VERSION ""

NS_ :

BS_:

BU_: SCU ADCU

BO_ 3221225472 VECTOR__INDEPENDENT_SIG_MSG: 0 Vector__XXX
 SG_ ADCU_SteerAngSpdLimt : 0|16@0+ (0.125,0) [0|1080] "deg/s" Vector__XXX
 SG_ ADCU_SteerWhlTorqReq : 0|11@0+ (0.01,-10.24) [-10.24|10.23] "Nm" Vector__XXX
 SG_ New_Signal_168 : 0|8@1+ (1,0) [0|0] "" Vector__XXX
 SG_ ADCU_3_Checksum : 0|8@0+ (1,0) [0|255] "-" Vector__XXX
 SG_ ADCU_3_MsgCounter : 0|4@0+ (1,0) [0|15] "-" Vector__XXX
 SG_ ADCU_2_Checksum : 0|8@0+ (1,0) [0|255] "" Vector__XXX
 SG_ ADCU_2_MsgCounter : 0|4@0+ (1,0) [0|15] "" Vector__XXX
 SG_ ADCU_1_Checksum : 0|8@0+ (1,0) [0|255] "" Vector__XXX
 SG_ ADCU_1_MsgCounter : 0|4@0+ (1,0) [0|15] "" Vector__XXX
 SG_ SCU_18_Checksum : 0|8@0+ (1,0) [0|255] "-" Vector__XXX
 SG_ VCU_GasPedalVirtualPstVD : 0|1@0+ (1,0) [0|1] "" Vector__XXX
 SG_ VCU_BrkPedalStVD : 0|1@0+ (1,0) [0|1] "" Vector__XXX
 SG_ SCU_18_MsgCounter : 0|4@0+ (1,0) [0|15] "-" Vector__XXX
 SG_ VCU_GasPedalVirtualPst : 0|8@0+ (0.392,0) [0|99.96] "%" Vector__XXX
 SG_ SCU_17_Checksum : 0|8@0+ (1,0) [0|255] "-" Vector__XXX
 SG_ SCU_17_MsgCounter : 0|4@0+ (1,0) [0|15] "-" Vector__XXX
 SG_ VCU_ACCButtInfo : 0|8@0+ (1,0) [0|255] "" Vector__XXX
 SG_ VCU_GasPedalActPstVD : 0|1@0+ (1,0) [0|1] "" Vector__XXX
 SG_ SCU_16_Checksum : 0|8@0+ (1,0) [0|205] "-" Vector__XXX
 SG_ SCU_16_MsgCounter : 0|4@0+ (1,0) [0|15] "-" Vector__XXX
 SG_ VCU_LateralAssistBtnInfoVD : 0|1@0+ (1,0) [0|1] "" Vector__XXX
 SG_ VCU_LateralAssistBtnInfo : 0|1@0+ (1,0) [0|1] "" Vector__XXX
 SG_ VCU_ACCMaxRecpDecelVD : 0|1@0+ (1,0) [0|1] "" Vector__XXX
 SG_ VCU_ACCMaxRecpDecel : 0|8@0+ (0.05,-5) [-5|7.75] "m/s2" Vector__XXX
 SG_ VCU_ActRecpTorq : 0|10@0+ (2,0) [0|2000] "Nm" Vector__XXX
 SG_ VCU_ActRecpTorqSt : 0|2@0+ (1,0) [0|3] "" Vector__XXX
 SG_ SCU_13_Checksum : 0|8@0+ (1,0) [0|255] "" Vector__XXX
 SG_ SCU_13_MsgCounter : 0|4@0+ (1,0) [0|15] "" Vector__XXX
 SG_ SCU_EStopSwStVD : 0|1@0+ (1,0) [0|1] "" Vector__XXX
 SG_ SCU_EStopSwSt : 0|1@0+ (1,0) [0|1] "" Vector__XXX
 SG_ SCU_12_Checksum : 0|8@0+ (1,0) [0|255] "" Vector__XXX
 SG_ SCU_12_MsgCounter : 0|4@0+ (1,0) [0|15] "" Vector__XXX
 SG_ SCU_11_Checksum : 0|8@0+ (1,0) [0|255] "" Vector__XXX
 SG_ SCU_11_MsgCounter : 0|4@0+ (1,0) [0|15] "" Vector__XXX
 SG_ BCM_RightTurnLampFaultSt : 0|1@0+ (1,0) [0|1] "" Vector__XXX
 SG_ BCM_LeftTurnLampFaultSt : 0|1@0+ (1,0) [0|1] "" Vector__XXX
 SG_ BCM_RRDoorAjarSt : 0|1@0+ (1,0) [0|1] "" Vector__XXX
 SG_ BCM_RLDoorAjarSt : 0|1@0+ (1,0) [0|1] "" Vector__XXX
 SG_ BCM_PsngrDoorAjarSt : 0|1@0+ (1,0) [0|1] "" Vector__XXX
 SG_ BCM_DriverDoorAjarSt : 0|1@0+ (1,0) [0|1] "" Vector__XXX
 SG_ BCM_RearFogLampSt : 0|1@0+ (1,0) [0|1] "" Vector__XXX
 SG_ BCM_FrontFogLampSt : 0|1@0+ (1,0) [0|1] "" Vector__XXX
 SG_ BCM_FrontWiperSt : 0|2@0+ (1,0) [0|3] "" Vector__XXX
 SG_ SCU_10_Checksum : 0|8@0+ (1,0) [0|255] "" Vector__XXX
 SG_ EPS_ThermalSt : 0|2@0+ (1,0) [0|3] "" Vector__XXX
 SG_ SCU_10_MsgCounter : 0|4@0+ (1,0) [0|15] "" Vector__XXX
 SG_ EPS_WarnLamp : 0|1@0+ (1,0) [0|1] "" Vector__XXX
 SG_ EPS_StrngWhlTorqVD : 0|1@0+ (1,0) [0|1] "" Vector__XXX
 SG_ SCU_9_Checksum : 0|8@0+ (1,0) [0|255] "" Vector__XXX
 SG_ EPB_FailSt : 0|1@0+ (1,0) [0|1] "" Vector__XXX
 SG_ SCU_9_MsgCounter : 0|4@0+ (1,0) [0|15] "" Vector__XXX
 SG_ EPB_SwitchStVD : 0|1@0+ (1,0) [0|1] "" Vector__XXX
 SG_ EPB_SwitchSt : 0|2@0+ (1,0) [0|3] "" Vector__XXX
 SG_ SCU_8_Checksum : 0|8@0+ (1,0) [0|255] "" Vector__XXX
 SG_ BCS_ActVehLaltrlAccelVD : 0|1@0+ (1,0) [0|1] "" Vector__XXX
 SG_ BCS_ActVehLongAccelVD : 0|1@0+ (1,0) [0|1] "" Vector__XXX
 SG_ SCU_8_MsgCounter : 0|4@0+ (1,0) [0|15] "" Vector__XXX
 SG_ BCS_VehLaltrlAccelOffset : 0|12@0+ (0.027126736,-21.593) [-21.593|21.593] "m/s^2" Vector__XXX
 SG_ BCS_VehLongAccelOffset : 0|12@0+ (0.027126736,-21.593) [-21.593|21.593] "m/s^2" Vector__XXX
 SG_ SCU_7_Checksum : 0|8@0+ (1,0) [0|255] "" Vector__XXX
 SG_ SCU_7_MsgCounter : 0|4@0+ (1,0) [0|15] "" Vector__XXX
 SG_ BCS_RRWheelSpd : 0|13@0+ (0.05625,0) [0|240] "km/h" Vector__XXX
 SG_ BCS_RRWheelSpdVD : 0|1@0+ (1,0) [0|1] "" Vector__XXX
 SG_ BCS_RRWheelRotatedDirection : 0|1@0+ (1,0) [0|1] "" Vector__XXX
 SG_ BCS_RRWheelRotatedDirectionVD : 0|1@0+ (1,0) [0|1] "" Vector__XXX
 SG_ BCS_RLWheelSpd : 0|13@0+ (0.05625,0) [0|240] "km/h" Vector__XXX
 SG_ BCS_RLWheelRotatedDirectionVD : 0|1@0+ (1,0) [0|1] "" Vector__XXX
 SG_ BCS_RLWheelRotatedDirection : 0|1@0+ (1,0) [0|1] "" Vector__XXX
 SG_ BCS_RLWheelSpdVD : 0|1@0+ (1,0) [0|1] "" Vector__XXX
 SG_ SCU_6_Checksum : 0|8@0+ (1,0) [0|255] "" Vector__XXX
 SG_ SCU_6_MsgCounter : 0|4@0+ (1,0) [0|15] "" Vector__XXX
 SG_ BCS_FRWheelSpd : 0|13@0+ (0.05625,0) [0|240] "km/h" Vector__XXX
 SG_ BCS_FRWheelSpdVD : 0|1@0+ (1,0) [0|1] "" Vector__XXX
 SG_ BCS_FRWheelRotatedDirection : 0|1@0+ (1,0) [0|1] "" Vector__XXX
 SG_ BCS_FRWheelRotatedDirectionVD : 0|1@0+ (1,0) [0|1] "" Vector__XXX
 SG_ BCS_FLWheelSpd : 0|13@0+ (0.05625,0) [0|240] "km/h" Vector__XXX
 SG_ BCS_FLWheelRotatedDirectionVD : 0|1@0+ (1,0) [0|1] "" Vector__XXX
 SG_ BCS_FLWheelRotatedDirection : 0|1@0+ (1,0) [0|1] "" Vector__XXX
 SG_ BCS_FLWheelSpdVD : 0|1@0+ (1,0) [0|1] "" Vector__XXX
 SG_ SCU_5_Checksum : 0|8@0+ (1,0) [0|255] "-" Vector__XXX
 SG_ BCS_CDDFail : 0|1@0+ (1,0) [0|1] "" Vector__XXX
 SG_ BCS_VehicleStandStillSt : 0|2@0+ (1,0) [0|3] "" Vector__XXX
 SG_ BCS_CDDAvailable : 0|1@0+ (1,0) [0|1] "" Vector__XXX
 SG_ BCS_CDDActive : 0|1@0+ (1,0) [0|1] "" Vector__XXX
 SG_ BCS_AEBAvailable : 0|1@0+ (1,0) [0|1] "" Vector__XXX
 SG_ BCS_AEBActive : 0|1@0+ (1,0) [0|1] "" Vector__XXX
 SG_ BCS_MasterCylinderPrOffset : 0|10@0+ (0.1,-15) [-15|15] "bar" Vector__XXX
 SG_ SCU_5_MsgCounter : 0|4@0+ (1,0) [0|15] "" Vector__XXX
 SG_ BCS_MasterCylinderPr : 0|12@0+ (0.1,0) [0|250] "bar" Vector__XXX
 SG_ BCS_MasterCylinderPrOffsetVD : 0|1@0+ (1,0) [0|1] "-" Vector__XXX
 SG_ BCS_MasterCylinderPrVD : 0|1@0+ (1,0) [0|1] "-" Vector__XXX
 SG_ BCS_NoBrakeForce : 0|1@0+ (1,0) [0|1] "" Vector__XXX
 SG_ SCU_4_Checksum : 0|8@0+ (1,0) [0|255] "-" Vector__XXX
 SG_ SCU_4_MsgCounter : 0|4@0+ (1,0) [0|15] "-" Vector__XXX
 SG_ BCS_HDCErrSt : 0|1@0+ (1,0) [0|1] "-" Vector__XXX
 SG_ BCS_HDCCtrlSt : 0|2@0+ (1,0) [0|3] "-" Vector__XXX
 SG_ SCU_3_Checksum : 0|8@0+ (1,0) [0|255] "" Vector__XXX
 SG_ SCU_3_MsgCounter : 0|4@0+ (1,0) [0|15] "" Vector__XXX
 SG_ BCS_YawRateSt : 0|1@0+ (1,0) [0|1] "" Vector__XXX
 SG_ SCU_2_Checksum : 0|8@0+ (1,0) [0|255] "" Vector__XXX
 SG_ SCU_2_MsgCounter : 0|4@0+ (1,0) [0|15] "" Vector__XXX
 SG_ BCS_RRWheelSpdEdgesSumVD : 0|1@0+ (1,0) [0|1] "" Vector__XXX
 SG_ BCS_RLWheelSpdEdgesSumVD : 0|1@0+ (1,0) [0|1] "" Vector__XXX
 SG_ BCS_FRWheelSpdEdgesSumVD : 0|1@0+ (1,0) [0|1] "" Vector__XXX
 SG_ BCS_FLWheelSpdEdgesSumVD : 0|1@0+ (1,0) [0|1] "" Vector__XXX
 SG_ BCS_RRWheelSpdEdgesSum : 0|12@0+ (1,0) [0|4095] "" Vector__XXX
 SG_ BCS_RLWheelSpdEdgesSum : 0|12@0+ (1,0) [0|4095] "" Vector__XXX
 SG_ BCS_FRWheelSpdEdgesSum : 0|12@0+ (1,0) [0|4095] "" Vector__XXX
 SG_ BCS_FLWheelSpdEdgesSum : 0|12@0+ (1,0) [0|4095] "" Vector__XXX
 SG_ SCU_1_Checksum : 0|8@0+ (1,0) [0|255] "-" Vector__XXX
 SG_ BCS_VDCActiveSt : 0|1@0+ (1,0) [0|1] "-" Vector__XXX
 SG_ SCU_1_MsgCounter : 0|4@0+ (1,0) [0|15] "-" Vector__XXX
 SG_ BCS_VDCFaultSt : 0|1@0+ (1,0) [0|1] "-" Vector__XXX
 SG_ BCS_ABSFaultSt : 0|1@0+ (1,0) [0|1] "-" Vector__XXX
 SG_ BCS_YawRateOffset : 0|12@0+ (0.0009765625,-0.13) [-0.13|0.13] "rad/s" Vector__XXX

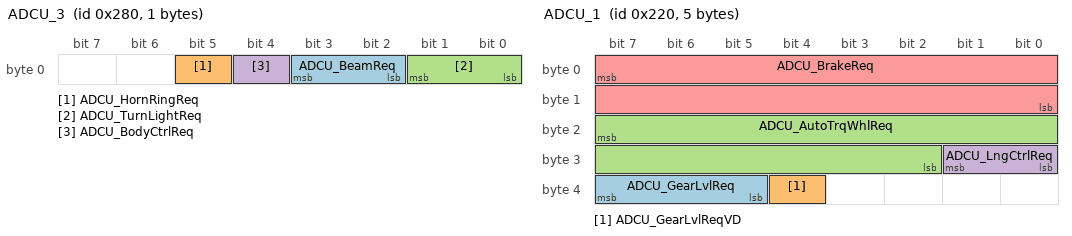
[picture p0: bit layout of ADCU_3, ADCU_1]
BO_ 640 ADCU_3: 1 ADCU
 SG_ ADCU_BeamReq : 3|2@0+ (1,0) [0|3] "-"  SCU
 SG_ ADCU_HornRingReq : 5|1@0+ (1,0) [0|1] "-"  SCU
 SG_ ADCU_TurnLightReq : 1|2@0+ (1,0) [0|3] "-"  SCU
 SG_ ADCU_BodyCtrlReq : 4|1@0+ (1,0) [0|1] "-"  SCU

BO_ 545 ADCU_2: 6 ADCU
 SG_ ADCU_SteerAngReq : 7|16@0+ (0.1,-780) [-780|779.9] "deg"  SCU
 SG_ ADCU_LatCtrlReq : 44|1@0+ (1,0) [0|1] "-"  SCU

BO_ 544 ADCU_1: 5 ADCU
 SG_ ADCU_GearLvlReq : 39|3@0+ (1,0) [0|7] ""  SCU
 SG_ ADCU_GearLvlReqVD : 36|1@0+ (1,0) [0|1] ""  SCU
 SG_ ADCU_AutoTrqWhlReq : 23|14@0+ (1,-5000) [-5000|5000] "Nm"  SCU
 SG_ ADCU_LngCtrlReq : 25|2@0+ (1,0) [0|3] ""  SCU
 SG_ ADCU_BrakeReq : 7|16@0+ (0.0004882,-16) [-16|16] "m/s^2"  SCU

BO_ 559 SCU_18: 7 SCU
 SG_ VCU_BrkPedalSt : 53|1@0+ (1,0) [0|1] ""  ADCU

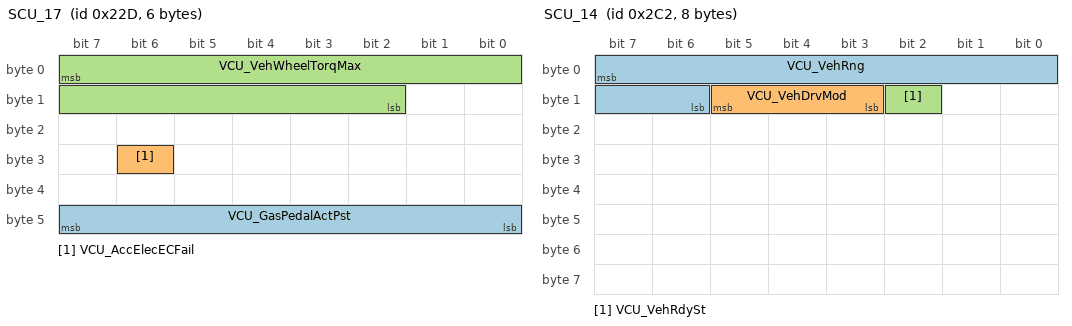
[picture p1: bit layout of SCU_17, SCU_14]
BO_ 557 SCU_17: 6 SCU
 SG_ VCU_GasPedalActPst : 47|8@0+ (0.392,0) [0|99.96] "%"  ADCU
 SG_ VCU_AccElecECFail : 30|1@0+ (1,0) [0|1] "-"  ADCU
 SG_ VCU_VehWheelTorqMax : 7|14@0+ (1,0) [0|10000] "Nm"  ADCU

BO_ 556 SCU_16: 6 SCU
 SG_ VCU_ActVehWheelTorq : 39|14@0+ (1,0) [0|10000] "Nm"  ADCU

BO_ 555 SCU_15: 5 SCU
 SG_ VCU_CrntGearLvl : 38|3@0+ (1,0) [0|7] ""  ADCU
 SG_ VCU_CrntGearLvlVD : 35|1@0+ (1,0) [0|1] ""  ADCU

BO_ 706 SCU_14: 8 SCU
 SG_ VCU_VehRng : 7|10@0+ (1,0) [0|1000] "km"  ADCU
 SG_ VCU_VehDrvMod : 13|3@0+ (1,0) [0|7] "-"  ADCU
 SG_ VCU_VehRdySt : 10|1@0+ (1,0) [0|1] "-"  ADCU

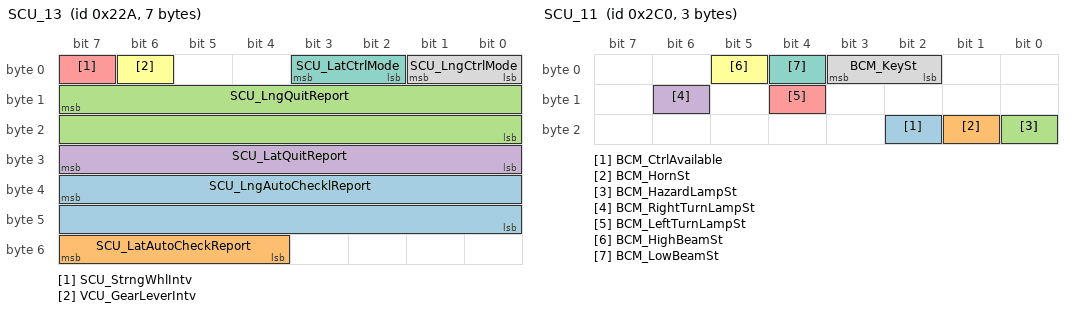
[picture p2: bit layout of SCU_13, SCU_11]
BO_ 554 SCU_13: 7 SCU
 SG_ SCU_LngAutoChecklReport : 39|16@0+ (1,0) [0|65535] "" Vector__XXX
 SG_ SCU_LatAutoCheckReport : 55|4@0+ (1,0) [0|15] "" Vector__XXX
 SG_ SCU_LngQuitReport : 15|16@0+ (1,0) [0|65535] "" Vector__XXX
 SG_ SCU_LatQuitReport : 31|8@0+ (1,0) [0|255] "" Vector__XXX
 SG_ SCU_StrngWhlIntv : 7|1@0+ (1,0) [0|1] ""  ADCU
 SG_ VCU_GearLeverIntv : 6|1@0+ (1,0) [0|1] ""  ADCU
 SG_ SCU_LatCtrlMode : 3|2@0+ (1,0) [0|3] ""  ADCU
 SG_ SCU_LngCtrlMode : 1|2@0+ (1,0) [0|3] ""  ADCU

BO_ 705 SCU_12: 1 SCU
 SG_ SRS_DriverSeatBeltSt : 3|2@0+ (1,0) [0|3] ""  ADCU
 SG_ SRS_PsngrSeatBeltSt : 1|2@0+ (1,0) [0|3] ""  ADCU

BO_ 704 SCU_11: 3 SCU
 SG_ BCM_CtrlAvailable : 18|1@0+ (1,0) [0|1] ""  ADCU
 SG_ BCM_HornSt : 17|1@0+ (1,0) [0|1] ""  ADCU
 SG_ BCM_HazardLampSt : 16|1@0+ (1,0) [0|1] ""  ADCU
 SG_ BCM_RightTurnLampSt : 14|1@0+ (1,0) [0|1] ""  ADCU
 SG_ BCM_LeftTurnLampSt : 12|1@0+ (1,0) [0|1] ""  ADCU
 SG_ BCM_HighBeamSt : 5|1@0+ (1,0) [0|1] ""  ADCU
 SG_ BCM_LowBeamSt : 4|1@0+ (1,0) [0|1] ""  ADCU
 SG_ BCM_KeySt : 3|2@0+ (1,0) [0|3] ""  ADCU

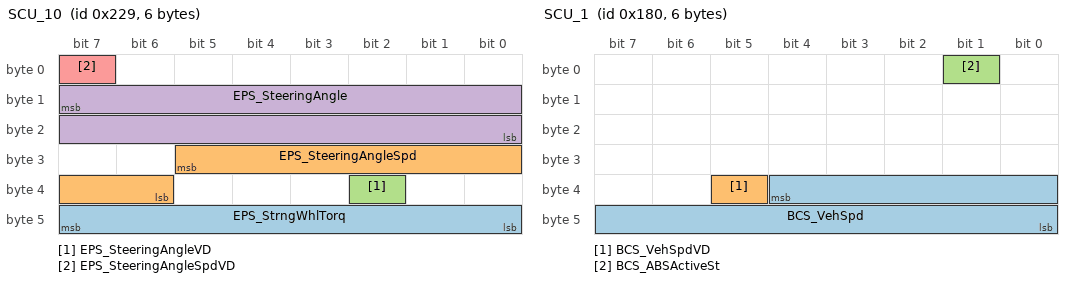
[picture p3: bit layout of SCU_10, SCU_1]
BO_ 553 SCU_10: 6 SCU
 SG_ EPS_StrngWhlTorq : 47|8@0+ (0.1,-12.7) [-12.5|12.5] "Nm"  ADCU
 SG_ EPS_SteeringAngleSpd : 29|8@0+ (4,0) [0|1016] "deg/sec"  ADCU
 SG_ EPS_SteeringAngleVD : 34|1@0+ (1,0) [0|1] ""  ADCU
 SG_ EPS_SteeringAngle : 15|16@0+ (0.1,-780) [-780|779.9] "deg"  ADCU
 SG_ EPS_SteeringAngleSpdVD : 7|1@0+ (1,0) [0|1] ""  ADCU

BO_ 552 SCU_9: 2 SCU
 SG_ EPB_SysSt : 10|3@0+ (1,0) [0|7] ""  ADCU

BO_ 551 SCU_8: 5 SCU
 SG_ BCS_ActVehLaltrlAccel : 31|12@0+ (0.027126736,-21.593) [-21.593|21.593] "m/s^2"  ADCU
 SG_ BCS_ActVehLongAccel : 7|12@0+ (0.027126736,-21.593) [-21.593|21.593] "m/s^2"  ADCU

BO_ 549 SCU_6: 0 SCU

BO_ 385 SCU_5: 0 SCU

BO_ 548 SCU_4: 0 SCU

BO_ 547 SCU_3: 2 SCU
 SG_ BCS_YawRate : 3|12@0+ (0.0009765625,-2.0943) [-2.0943|1.9047234375] "rad/s"  ADCU

BO_ 546 SCU_2: 0 SCU

BO_ 384 SCU_1: 6 SCU
 SG_ BCS_VehSpd : 36|13@0+ (0.05625,0) [0|240] "km/h"  ADCU
 SG_ BCS_VehSpdVD : 37|1@0+ (1,0) [0|1] "-"  ADCU
 SG_ BCS_ABSActiveSt : 1|1@0+ (1,0) [0|1] "-"  ADCU

CM_ BO_ 3221225472 "This is a message for not used signals, created by Vector CANdb++ DBC OLE DB Provider.";
CM_ SG_ 3221225472 ADCU_SteerAngSpdLimt "Limitation of steering angular speed， EPS will not let the angular speed of steering wheel be over this limitation: only active in automatic driving mode";
CM_ SG_ 3221225472 ADCU_SteerWhlTorqReq "Demand torque of steering wheel((turn left+ turn right-))";
CM_ SG_ 3221225472 ADCU_3_Checksum "Message checksum";
CM_ SG_ 3221225472 ADCU_3_MsgCounter "Message counter of ADCU_3";
CM_ SG_ 3221225472 ADCU_2_Checksum "Message checksum";
CM_ SG_ 3221225472 ADCU_2_MsgCounter "Message counter of ADCU_2";
CM_ SG_ 3221225472 ADCU_1_Checksum "Message checksum";
CM_ SG_ 3221225472 ADCU_1_MsgCounter "Message counter of ADCU_1";
CM_ SG_ 3221225472 SCU_18_Checksum "Checksum signal for frame";
CM_ SG_ 3221225472 VCU_GasPedalVirtualPstVD "Virtual position of gas pedal position validity.";
CM_ SG_ 3221225472 VCU_BrkPedalStVD "VCU_BrakePedSt valid data";
CM_ SG_ 3221225472 SCU_18_MsgCounter "Message counter signal for frame";
CM_ SG_ 3221225472 VCU_GasPedalVirtualPst "Virtual position of gas pedal position.";
CM_ SG_ 3221225472 SCU_17_Checksum "Checksum signal for frame";
CM_ SG_ 3221225472 SCU_17_MsgCounter "Message counter signal for frame";
CM_ SG_ 3221225472 VCU_ACCButtInfo "ACC Button Information";
CM_ SG_ 3221225472 VCU_GasPedalActPstVD "Actual position of gas pedal validity.";
CM_ SG_ 3221225472 SCU_16_Checksum "Message checksum";
CM_ SG_ 3221225472 SCU_16_MsgCounter "The MessageCounter is a 0 ~ 15 counter, increased of one unit on every message transmission";
CM_ SG_ 3221225472 VCU_LateralAssistBtnInfoVD "Lateral assist button Information valid data";
CM_ SG_ 3221225472 VCU_LateralAssistBtnInfo "Lateral assist button Information";
CM_ SG_ 3221225472 VCU_ACCMaxRecpDecelVD "VCU_ACCMaxRecpDecel valid validity";
CM_ SG_ 3221225472 VCU_ACCMaxRecpDecel "Current maximum recuperation deceleration of generator";
CM_ SG_ 3221225472 VCU_ActRecpTorq "Current recuperation torque of generator";
CM_ SG_ 3221225472 VCU_ActRecpTorqSt "Status of recuperation torque of generator";
CM_ SG_ 3221225472 SCU_13_Checksum "Message checksum";
CM_ SG_ 3221225472 SCU_13_MsgCounter "The message counter is a 0-15 counter, increased of one unit on every message transmission";
CM_ SG_ 3221225472 SCU_EStopSwStVD "Emergency switch status validity";
CM_ SG_ 3221225472 SCU_EStopSwSt "Emergency switch status";
CM_ SG_ 3221225472 SCU_12_Checksum "Message checksum";
CM_ SG_ 3221225472 SCU_12_MsgCounter "The message counter is a 0-15 counter, increased of one unit on every message transmission";
CM_ SG_ 3221225472 SCU_11_MsgCounter "Message counter";
CM_ SG_ 3221225472 BCM_RightTurnLampFaultSt "Right turn lamp fault status";
CM_ SG_ 3221225472 BCM_LeftTurnLampFaultSt "Left turn lamp fault status";
CM_ SG_ 3221225472 BCM_RRDoorAjarSt "Rear right door ajar status";
CM_ SG_ 3221225472 BCM_RLDoorAjarSt "Rear left door ajar status";
CM_ SG_ 3221225472 BCM_PsngrDoorAjarSt "Passenger door ajar status";
CM_ SG_ 3221225472 BCM_DriverDoorAjarSt "Driver door ajar status";
CM_ SG_ 3221225472 BCM_RearFogLampSt "Rear fog lamp status";
CM_ SG_ 3221225472 BCM_FrontFogLampSt "Front fog lamp status";
CM_ SG_ 3221225472 BCM_FrontWiperSt "Front wiper status";
CM_ SG_ 3221225472 SCU_10_Checksum "Message checksum";
CM_ SG_ 3221225472 EPS_ThermalSt "System Thermal status";
CM_ SG_ 3221225472 SCU_10_MsgCounter "Check the MessageCounter consistency atleast on every message reception";
CM_ SG_ 3221225472 EPS_WarnLamp "Steering Warning Lamp";
CM_ SG_ 3221225472 EPS_StrngWhlTorqVD "Steering Wheel Torque valid value";
CM_ SG_ 3221225472 SCU_9_Checksum "Message checksum";
CM_ SG_ 3221225472 EPB_FailSt "EPB fail status,to indicate wether EPB can response to external apply  request or not";
CM_ SG_ 3221225472 SCU_9_MsgCounter "Message counter";
CM_ SG_ 3221225472 EPB_SwitchStVD "EPB switch status validity";
CM_ SG_ 3221225472 EPB_SwitchSt "EPB switch status";
CM_ SG_ 3221225472 BCS_ActVehLaltrlAccelVD "Quality/fault information to actual vehicle lateral acceleration";
CM_ SG_ 3221225472 BCS_ActVehLongAccelVD "Quality/fault information to actual vehicle longitudinal acceleration";
CM_ SG_ 3221225472 SCU_8_MsgCounter "The message counter is a 0-15 counter, increased of one unit on every message transmission";
CM_ SG_ 3221225472 BCS_VehLaltrlAccelOffset "Actual vehicle lateral acceleration offset";
CM_ SG_ 3221225472 BCS_VehLongAccelOffset "Actual vehicle longitudinal acceleration offset";
CM_ SG_ 3221225472 SCU_7_MsgCounter "The message counter is a 0-15 counter, increased of one unit on every message transmission";
CM_ SG_ 3221225472 BCS_RRWheelSpd "Current wheel speed information of rear right wheel";
CM_ SG_ 3221225472 BCS_RRWheelSpdVD "Quality/fault information to current wheel speed of RRont left wheel,be used for validity of BCS_RRWheelSpd and BCS_RRWheelSpdEdgesSum signal";
CM_ SG_ 3221225472 BCS_RRWheelRotatedDirection "RR wheel rotate direction";
CM_ SG_ 3221225472 BCS_RRWheelRotatedDirectionVD "RR wheel rotate direction validity";
CM_ SG_ 3221225472 BCS_RLWheelSpd "Current wheel speed information of rear left wheel";
CM_ SG_ 3221225472 BCS_RLWheelRotatedDirectionVD "RL wheel rotate direction validity";
CM_ SG_ 3221225472 BCS_RLWheelRotatedDirection "RL wheel rotate direction";
CM_ SG_ 3221225472 BCS_RLWheelSpdVD "Quality/fault information to current wheel speed of front left wheel,be used for validity of BCS_RLWheelSpd and BCS_RLWheelSpdEdgesSum signal";
CM_ SG_ 3221225472 SCU_6_MsgCounter "The message counter is a 0-15 counter, increased of one unit on every message transmission";
CM_ SG_ 3221225472 BCS_FRWheelSpd "Current wheel speed information of front right wheel";
CM_ SG_ 3221225472 BCS_FRWheelSpdVD "Quality/fault information to current wheel speed of front left wheel,be used for validity of BCS_FRWheelSpd and BCS_FRWheelSpdEdgesSum signal";
CM_ SG_ 3221225472 BCS_FRWheelRotatedDirection "FR wheel rotate direction";
CM_ SG_ 3221225472 BCS_FRWheelRotatedDirectionVD "FR wheel rotate direction validity";
CM_ SG_ 3221225472 BCS_FLWheelSpd "Current wheel speed information of front left wheel";
CM_ SG_ 3221225472 BCS_FLWheelRotatedDirectionVD "FL wheel rotate direction validity";
CM_ SG_ 3221225472 BCS_FLWheelRotatedDirection "FL wheel rotate direction";
CM_ SG_ 3221225472 BCS_FLWheelSpdVD "Quality/fault information to current wheel speed of front left wheel,be used for validity of BCS_FLWheelSpd and BCS_FLWheelSpdEdgesSum signal";
CM_ SG_ 3221225472 BCS_CDDFail "CDD in failure";
CM_ SG_ 3221225472 BCS_VehicleStandStillSt "Indicating whether the vehicle is standstill or not;
must not be set until standstill is surely reached.";
CM_ SG_ 3221225472 BCS_CDDAvailable "CDD(Controlled Deceleration for Driver) is available";
CM_ SG_ 3221225472 BCS_CDDActive "CDD(Controlled Deceleration for Driver) is active";
CM_ SG_ 3221225472 BCS_AEBAvailable "AEB(Automatic Emergency
Braking) is available";
CM_ SG_ 3221225472 BCS_AEBActive "AEB(Automatic Emergency
Braking) is active (in deceleration)";
CM_ SG_ 3221225472 BCS_MasterCylinderPrOffset "Master cylinder pressure offset";
CM_ SG_ 3221225472 BCS_MasterCylinderPr "Master cylinder pressure";
CM_ SG_ 3221225472 BCS_MasterCylinderPrOffsetVD "Master cylinder pressure offset valid value";
CM_ SG_ 3221225472 BCS_MasterCylinderPrVD "The valid value of BCS_MasterCylinderPr";
CM_ SG_ 3221225472 BCS_NoBrakeForce "No brake pressure applied,generally it regards wheel cylinder presure";
CM_ SG_ 3221225472 SCU_4_Checksum "Message checksum";
CM_ SG_ 3221225472 SCU_4_MsgCounter "Message counter";
CM_ SG_ 3221225472 BCS_HDCErrSt "HDC error Status";
CM_ SG_ 3221225472 BCS_HDCCtrlSt "HDC(Hill Descent Control) Control status";
CM_ SG_ 3221225472 SCU_3_Checksum "Message checksum";
CM_ SG_ 3221225472 BCS_YawRateSt "Yaw rate status";
CM_ SG_ 3221225472 SCU_2_MsgCounter "The message counter is a 0-15 counter, increased of one unit on every message transmission";
CM_ SG_ 3221225472 BCS_RRWheelSpdEdgesSumVD "Quality/fault information to current wheel speed edges sum of rear right wheel";
CM_ SG_ 3221225472 BCS_RLWheelSpdEdgesSumVD "Quality/fault information to current wheel speed edges sum of rear left wheel";
CM_ SG_ 3221225472 BCS_FRWheelSpdEdgesSumVD "Quality/fault information to current wheel speed edges sum of front right wheel";
CM_ SG_ 3221225472 BCS_FLWheelSpdEdgesSumVD "Quality/fault information to current wheel speed edges sum of front left wheel";
CM_ SG_ 3221225472 BCS_RRWheelSpdEdgesSum "Accumulated sum of rising and falling edges of  rear right wheel speed sensor output·since IGN ON( the wheel plate have 43 teeth/cycle,the edge is 86)";
CM_ SG_ 3221225472 BCS_RLWheelSpdEdgesSum "Accumulated sum of rising and falling edges of rear left wheel speed sensor output·since IGN ON( the wheel plate have 43teeth/cycle,the edge is 86)";
CM_ SG_ 3221225472 BCS_FRWheelSpdEdgesSum "Accumulated sum of rising and falling edges of front right wheel speed sensor output·since IGN ON( the wheel plate have 43 teeth/cycle,the edge is 86)";
CM_ SG_ 3221225472 BCS_FLWheelSpdEdgesSum "Accumulated sum of rising and falling edges of front left wheel speed sensor output·since IGN ON( the wheel plate have 43 teeth/cycle,the edge is 86)";
CM_ SG_ 3221225472 BCS_VDCActiveSt "Indication that VDC system currently performs a brake/engine intervention";
CM_ SG_ 3221225472 SCU_1_MsgCounter "The MessageCounter is a 0 ~ 15 counter, increased of one unit on every message transmission";
CM_ SG_ 3221225472 BCS_VDCFaultSt "VDC is switched off due to detected failure";
CM_ SG_ 3221225472 BCS_ABSFaultSt "ABS system has detected a failure which does no allow a reliable ABS regulation and is therefore switched off";
CM_ SG_ 3221225472 BCS_YawRateOffset "Yaw rate offset";
CM_ SG_ 640 ADCU_BeamReq "近光灯、远光灯控制请求";
CM_ SG_ 640 ADCU_HornRingReq "喇叭控制请求";
CM_ SG_ 640 ADCU_TurnLightReq "转向灯、双闪灯控制请求指令";
CM_ SG_ 640 ADCU_BodyCtrlReq "车身电子控制请求激活、退出指令";
CM_ SG_ 545 ADCU_SteerAngReq "方向盘转角请求，左“+”右“-”，单位为deg，只在横向处于自动控制模式时有效";
CM_ SG_ 545 ADCU_LatCtrlReq "纵向控制请求进入手动、自动的指令";
CM_ SG_ 544 ADCU_GearLvlReq "挡位请求指令，处于P挡时，车辆将自动拉起手刹，，只在纵向处于自动控制模式时有效";
CM_ SG_ 544 ADCU_GearLvlReqVD "挡位请求有效、无效指令";
CM_ SG_ 544 ADCU_AutoTrqWhlReq "自动驾驶模式下的扭矩请求，单位Nm，只在纵向处于自动控制模式时有效";
CM_ SG_ 544 ADCU_LngCtrlReq "纵向控制请求进入手动、自动的指令";
CM_ SG_ 544 ADCU_BrakeReq "自动驾驶模式下的制动加速度控制指令，单位m/s^2，只在纵向处于自动控制模式时有效";
CM_ SG_ 559 VCU_BrkPedalSt "制动踏板被踩下的状态反馈";
CM_ SG_ 557 VCU_GasPedalActPst "油门踏板实际位置";
CM_ SG_ 557 VCU_AccElecECFail "驱动系统故障";
CM_ SG_ 557 VCU_VehWheelTorqMax "驱动系统允许的最大扭矩值";
CM_ SG_ 556 VCU_ActVehWheelTorq "轮端扭矩的实际值";
CM_ SG_ 555 VCU_CrntGearLvl "实际挡位信号";
CM_ SG_ 555 VCU_CrntGearLvlVD "实际挡位信号的有效性判断";
CM_ SG_ 706 VCU_VehRng "续航里程";
CM_ SG_ 706 VCU_VehDrvMod "车辆行驶模式";
CM_ SG_ 706 VCU_VehRdySt "整车ready状态";
CM_ SG_ 554 SCU_LngAutoChecklReport "是否满足纵向控制从手动切换为自动的激活条件的反馈";
CM_ SG_ 554 SCU_LatAutoCheckReport "是否满足横向控制从手动切换为自动的激活条件的反馈";
CM_ SG_ 554 SCU_LngQuitReport "纵向控制非预期从自动切换为退出的反馈";
CM_ SG_ 554 SCU_LatQuitReport "横向控制非预期从自动切换为退出的反馈";
CM_ SG_ 554 SCU_StrngWhlIntv "方向盘干预状态反馈";
CM_ SG_ 554 VCU_GearLeverIntv "挡位干预状态反馈";
CM_ SG_ 554 SCU_LatCtrlMode "纵向控制模式";
CM_ SG_ 554 SCU_LngCtrlMode "纵向控制模式";
CM_ SG_ 705 SRS_DriverSeatBeltSt "驾驶位安全带状态";
CM_ SG_ 705 SRS_PsngrSeatBeltSt "副驾驶位安全带状态";
CM_ SG_ 704 BCM_CtrlAvailable "车身电子控制状态";
CM_ SG_ 704 BCM_HornSt "喇叭状态";
CM_ SG_ 704 BCM_HazardLampSt "双闪灯状态";
CM_ SG_ 704 BCM_RightTurnLampSt "右转向灯状态";
CM_ SG_ 704 BCM_LeftTurnLampSt "左转向灯状态";
CM_ SG_ 704 BCM_HighBeamSt "远光灯状态";
CM_ SG_ 704 BCM_LowBeamSt "近光灯状态";
CM_ SG_ 704 BCM_KeySt "整车上电状态";
CM_ SG_ 553 EPS_StrngWhlTorq "助力扭矩";
CM_ SG_ 553 EPS_SteeringAngleSpd "方向盘转角速度";
CM_ SG_ 553 EPS_SteeringAngleVD "方向盘转角实际值有效性判断";
CM_ SG_ 553 EPS_SteeringAngle "方向盘转角实际值";
CM_ SG_ 553 EPS_SteeringAngleSpdVD "方向盘转角速度实际值的有效性判断";
CM_ SG_ 552 EPB_SysSt "EPB系统状态值";
CM_ SG_ 551 BCS_ActVehLaltrlAccel "横向加速度实际值";
CM_ SG_ 551 BCS_ActVehLongAccel "纵向加速度实际值";
CM_ SG_ 547 BCS_YawRate "横摆角速度";
CM_ SG_ 384 BCS_VehSpd "车速信号";
CM_ SG_ 384 BCS_VehSpdVD "车速信号的有效性判断";
CM_ SG_ 384 BCS_ABSActiveSt "ABS激活状态反馈值";
BA_DEF_  "BusType" STRING ;
BA_DEF_ SG_  "Remark" STRING ;
BA_DEF_ SG_  "EventCommandSignal" ENUM  "No","Yes";
BA_DEF_ SG_  "GatewayedSignals" ENUM  "No","Yes";
BA_DEF_ SG_  "GenSigTimeoutValue" INT 0 0;
BA_DEF_ SG_  "GenSigStartValue" INT 0 0;
BA_DEF_ SG_  "GenSigInvalidValue" INT 0 0;
BA_DEF_ SG_  "GenSigInactiveValue" INT 0 0;
BA_DEF_ BO_  "GenMsgCycleTimeFast" INT 0 0;
BA_DEF_ BO_  "GenMsgCycleTime" INT 0 0;
BA_DEF_ SG_  "GenSigSendType" ENUM  "Trigger","Passive";
BA_DEF_ BO_  "GenMsgSendType" ENUM  "Periodic","Event","IfActive","POE","PA";
BA_DEF_DEF_  "BusType" "";
BA_DEF_DEF_  "Remark" "*";
BA_DEF_DEF_  "EventCommandSignal" "No";
BA_DEF_DEF_  "GatewayedSignals" "No";
BA_DEF_DEF_  "GenSigTimeoutValue" 0;
BA_DEF_DEF_  "GenSigStartValue" 0;
BA_DEF_DEF_  "GenSigInvalidValue" 0;
BA_DEF_DEF_  "GenSigInactiveValue" 0;
BA_DEF_DEF_  "GenMsgCycleTimeFast" 0;
BA_DEF_DEF_  "GenMsgCycleTime" 0;
BA_DEF_DEF_  "GenSigSendType" "Trigger";
BA_DEF_DEF_  "GenMsgSendType" "Periodic";
BA_ "BusType" "CAN";
BA_ "GenMsgCycleTime" BO_ 640 50;
BA_ "GenMsgCycleTime" BO_ 545 20;
BA_ "GenMsgCycleTime" BO_ 544 20;
BA_ "GenMsgCycleTime" BO_ 559 20;
BA_ "GenMsgCycleTime" BO_ 557 20;
BA_ "GenMsgCycleTime" BO_ 556 20;
BA_ "GenMsgCycleTime" BO_ 555 20;
BA_ "GenMsgCycleTime" BO_ 706 100;
BA_ "GenMsgCycleTime" BO_ 554 20;
BA_ "GenMsgCycleTime" BO_ 705 100;
BA_ "GenMsgCycleTime" BO_ 704 100;
BA_ "GenMsgCycleTime" BO_ 553 20;
BA_ "GenMsgCycleTime" BO_ 552 20;
BA_ "GenMsgCycleTime" BO_ 551 20;
BA_ "GenMsgCycleTime" BO_ 549 20;
BA_ "GenMsgCycleTime" BO_ 385 10;
BA_ "GenMsgCycleTime" BO_ 548 20;
BA_ "GenMsgCycleTime" BO_ 547 20;
BA_ "GenMsgCycleTime" BO_ 546 20;
BA_ "GenMsgCycleTime" BO_ 384 10;
BA_ "GenSigSendType" SG_ 3221225472 ADCU_SteerAngSpdLimt 1;
BA_ "Remark" SG_ 3221225472 ADCU_SteerAngSpdLimt "";
BA_ "GenSigSendType" SG_ 3221225472 ADCU_SteerWhlTorqReq 1;
BA_ "Remark" SG_ 3221225472 ADCU_SteerWhlTorqReq "";
BA_ "GenSigSendType" SG_ 3221225472 ADCU_3_Checksum 1;
BA_ "Remark" SG_ 3221225472 ADCU_3_Checksum "";
BA_ "GenSigSendType" SG_ 3221225472 ADCU_3_MsgCounter 1;
BA_ "Remark" SG_ 3221225472 ADCU_3_MsgCounter "";
BA_ "GenSigSendType" SG_ 3221225472 ADCU_2_Checksum 1;
BA_ "Remark" SG_ 3221225472 ADCU_2_Checksum "";
BA_ "GenSigSendType" SG_ 3221225472 ADCU_2_MsgCounter 1;
BA_ "Remark" SG_ 3221225472 ADCU_2_MsgCounter "";
BA_ "GenSigSendType" SG_ 3221225472 ADCU_1_Checksum 1;
BA_ "Remark" SG_ 3221225472 ADCU_1_Checksum "";
BA_ "GenSigSendType" SG_ 3221225472 ADCU_1_MsgCounter 1;
BA_ "Remark" SG_ 3221225472 ADCU_1_MsgCounter "";
BA_ "GenSigSendType" SG_ 3221225472 SCU_18_Checksum 1;
BA_ "Remark" SG_ 3221225472 SCU_18_Checksum "";
BA_ "GenSigSendType" SG_ 3221225472 VCU_GasPedalVirtualPstVD 1;
BA_ "Remark" SG_ 3221225472 VCU_GasPedalVirtualPstVD "";
BA_ "GenSigSendType" SG_ 3221225472 VCU_BrkPedalStVD 1;
BA_ "Remark" SG_ 3221225472 VCU_BrkPedalStVD "";
BA_ "GenSigSendType" SG_ 3221225472 SCU_18_MsgCounter 1;
BA_ "Remark" SG_ 3221225472 SCU_18_MsgCounter "";
BA_ "GenSigSendType" SG_ 3221225472 VCU_GasPedalVirtualPst 1;
BA_ "Remark" SG_ 3221225472 VCU_GasPedalVirtualPst "";
BA_ "GenSigSendType" SG_ 3221225472 SCU_17_Checksum 1;
BA_ "Remark" SG_ 3221225472 SCU_17_Checksum "";
BA_ "GenSigSendType" SG_ 3221225472 SCU_17_MsgCounter 1;
BA_ "Remark" SG_ 3221225472 SCU_17_MsgCounter "";
BA_ "GenSigSendType" SG_ 3221225472 VCU_ACCButtInfo 1;
BA_ "Remark" SG_ 3221225472 VCU_ACCButtInfo "";
BA_ "GenSigSendType" SG_ 3221225472 VCU_GasPedalActPstVD 1;
BA_ "Remark" SG_ 3221225472 VCU_GasPedalActPstVD "";
BA_ "GenSigStartValue" SG_ 3221225472 SCU_16_Checksum 85;
BA_ "GenSigSendType" SG_ 3221225472 SCU_16_Checksum 1;
BA_ "Remark" SG_ 3221225472 SCU_16_Checksum "";
BA_ "GenSigSendType" SG_ 3221225472 SCU_16_MsgCounter 1;
BA_ "Remark" SG_ 3221225472 SCU_16_MsgCounter "";
BA_ "GenSigSendType" SG_ 3221225472 VCU_LateralAssistBtnInfoVD 1;
BA_ "Remark" SG_ 3221225472 VCU_LateralAssistBtnInfoVD "";
BA_ "GenSigSendType" SG_ 3221225472 VCU_LateralAssistBtnInfo 1;
BA_ "Remark" SG_ 3221225472 VCU_LateralAssistBtnInfo "";
BA_ "GenSigSendType" SG_ 3221225472 VCU_ACCMaxRecpDecelVD 1;
BA_ "Remark" SG_ 3221225472 VCU_ACCMaxRecpDecelVD "";
BA_ "GenSigSendType" SG_ 3221225472 VCU_ACCMaxRecpDecel 1;
BA_ "Remark" SG_ 3221225472 VCU_ACCMaxRecpDecel "";
BA_ "GenSigSendType" SG_ 3221225472 VCU_ActRecpTorq 1;
BA_ "Remark" SG_ 3221225472 VCU_ActRecpTorq "";
BA_ "GenSigSendType" SG_ 3221225472 VCU_ActRecpTorqSt 1;
BA_ "Remark" SG_ 3221225472 VCU_ActRecpTorqSt "";
BA_ "GenSigSendType" SG_ 3221225472 SCU_13_Checksum 1;
BA_ "Remark" SG_ 3221225472 SCU_13_Checksum "";
BA_ "GenSigSendType" SG_ 3221225472 SCU_13_MsgCounter 1;
BA_ "Remark" SG_ 3221225472 SCU_13_MsgCounter "";
BA_ "GenSigSendType" SG_ 3221225472 SCU_EStopSwStVD 1;
BA_ "Remark" SG_ 3221225472 SCU_EStopSwStVD "";
BA_ "GenSigSendType" SG_ 3221225472 SCU_EStopSwSt 1;
BA_ "Remark" SG_ 3221225472 SCU_EStopSwSt "";
BA_ "GenSigSendType" SG_ 3221225472 SCU_12_Checksum 1;
BA_ "Remark" SG_ 3221225472 SCU_12_Checksum "";
BA_ "GenSigSendType" SG_ 3221225472 SCU_12_MsgCounter 1;
BA_ "Remark" SG_ 3221225472 SCU_12_MsgCounter "";
BA_ "GenSigStartValue" SG_ 3221225472 SCU_11_Checksum 85;
BA_ "GenSigSendType" SG_ 3221225472 SCU_11_Checksum 1;
BA_ "Remark" SG_ 3221225472 SCU_11_Checksum "";
BA_ "GenSigSendType" SG_ 3221225472 SCU_11_MsgCounter 1;
BA_ "Remark" SG_ 3221225472 SCU_11_MsgCounter "";
BA_ "GenSigSendType" SG_ 3221225472 BCM_RightTurnLampFaultSt 1;
BA_ "Remark" SG_ 3221225472 BCM_RightTurnLampFaultSt "";
BA_ "GenSigTimeoutValue" SG_ 3221225472 BCM_RightTurnLampFaultSt 1;
BA_ "GenSigSendType" SG_ 3221225472 BCM_LeftTurnLampFaultSt 1;
BA_ "Remark" SG_ 3221225472 BCM_LeftTurnLampFaultSt "";
BA_ "GenSigTimeoutValue" SG_ 3221225472 BCM_LeftTurnLampFaultSt 1;
BA_ "GenSigSendType" SG_ 3221225472 BCM_RRDoorAjarSt 1;
BA_ "Remark" SG_ 3221225472 BCM_RRDoorAjarSt "";
BA_ "GenSigSendType" SG_ 3221225472 BCM_RLDoorAjarSt 1;
BA_ "Remark" SG_ 3221225472 BCM_RLDoorAjarSt "";
BA_ "GenSigSendType" SG_ 3221225472 BCM_PsngrDoorAjarSt 1;
BA_ "Remark" SG_ 3221225472 BCM_PsngrDoorAjarSt "";
BA_ "GenSigSendType" SG_ 3221225472 BCM_DriverDoorAjarSt 1;
BA_ "Remark" SG_ 3221225472 BCM_DriverDoorAjarSt "";
BA_ "GenSigSendType" SG_ 3221225472 BCM_RearFogLampSt 1;
BA_ "Remark" SG_ 3221225472 BCM_RearFogLampSt "";
BA_ "GenSigSendType" SG_ 3221225472 BCM_FrontFogLampSt 1;
BA_ "Remark" SG_ 3221225472 BCM_FrontFogLampSt "";
BA_ "GenSigSendType" SG_ 3221225472 BCM_FrontWiperSt 1;
BA_ "Remark" SG_ 3221225472 BCM_FrontWiperSt "";
BA_ "GenSigStartValue" SG_ 3221225472 SCU_10_Checksum 255;
BA_ "GenSigSendType" SG_ 3221225472 SCU_10_Checksum 1;
BA_ "Remark" SG_ 3221225472 SCU_10_Checksum "";
BA_ "GenSigSendType" SG_ 3221225472 EPS_ThermalSt 1;
BA_ "Remark" SG_ 3221225472 EPS_ThermalSt "";
BA_ "GenSigSendType" SG_ 3221225472 SCU_10_MsgCounter 1;
BA_ "Remark" SG_ 3221225472 SCU_10_MsgCounter "";
BA_ "GenSigSendType" SG_ 3221225472 EPS_WarnLamp 1;
BA_ "Remark" SG_ 3221225472 EPS_WarnLamp "";
BA_ "GenSigTimeoutValue" SG_ 3221225472 EPS_WarnLamp 1;
BA_ "GenSigSendType" SG_ 3221225472 EPS_StrngWhlTorqVD 1;
BA_ "Remark" SG_ 3221225472 EPS_StrngWhlTorqVD "";
BA_ "GenSigSendType" SG_ 3221225472 SCU_9_Checksum 1;
BA_ "Remark" SG_ 3221225472 SCU_9_Checksum "";
BA_ "GenSigSendType" SG_ 3221225472 EPB_FailSt 1;
BA_ "Remark" SG_ 3221225472 EPB_FailSt "";
BA_ "GenSigTimeoutValue" SG_ 3221225472 EPB_FailSt 1;
BA_ "GenSigSendType" SG_ 3221225472 SCU_9_MsgCounter 1;
BA_ "Remark" SG_ 3221225472 SCU_9_MsgCounter "";
BA_ "GenSigSendType" SG_ 3221225472 EPB_SwitchStVD 1;
BA_ "Remark" SG_ 3221225472 EPB_SwitchStVD "";
BA_ "GenSigSendType" SG_ 3221225472 EPB_SwitchSt 1;
BA_ "Remark" SG_ 3221225472 EPB_SwitchSt "";
BA_ "GenSigStartValue" SG_ 3221225472 SCU_8_Checksum 85;
BA_ "GenSigSendType" SG_ 3221225472 SCU_8_Checksum 1;
BA_ "Remark" SG_ 3221225472 SCU_8_Checksum "";
BA_ "GenSigSendType" SG_ 3221225472 BCS_ActVehLaltrlAccelVD 1;
BA_ "Remark" SG_ 3221225472 BCS_ActVehLaltrlAccelVD "";
BA_ "GenSigSendType" SG_ 3221225472 BCS_ActVehLongAccelVD 1;
BA_ "Remark" SG_ 3221225472 BCS_ActVehLongAccelVD "";
BA_ "GenSigSendType" SG_ 3221225472 SCU_8_MsgCounter 1;
BA_ "Remark" SG_ 3221225472 SCU_8_MsgCounter "";
BA_ "GenSigStartValue" SG_ 3221225472 BCS_VehLaltrlAccelOffset 796;
BA_ "GenSigSendType" SG_ 3221225472 BCS_VehLaltrlAccelOffset 1;
BA_ "Remark" SG_ 3221225472 BCS_VehLaltrlAccelOffset "";
BA_ "GenSigStartValue" SG_ 3221225472 BCS_VehLongAccelOffset 796;
BA_ "GenSigSendType" SG_ 3221225472 BCS_VehLongAccelOffset 1;
BA_ "Remark" SG_ 3221225472 BCS_VehLongAccelOffset "";
BA_ "GenSigStartValue" SG_ 3221225472 SCU_7_Checksum 85;
BA_ "GenSigSendType" SG_ 3221225472 SCU_7_Checksum 1;
BA_ "Remark" SG_ 3221225472 SCU_7_Checksum "";
BA_ "GenSigSendType" SG_ 3221225472 SCU_7_MsgCounter 1;
BA_ "Remark" SG_ 3221225472 SCU_7_MsgCounter "";
BA_ "GenSigSendType" SG_ 3221225472 BCS_RRWheelSpd 1;
BA_ "Remark" SG_ 3221225472 BCS_RRWheelSpd "";
BA_ "GenSigSendType" SG_ 3221225472 BCS_RRWheelSpdVD 1;
BA_ "Remark" SG_ 3221225472 BCS_RRWheelSpdVD "";
BA_ "GenSigSendType" SG_ 3221225472 BCS_RRWheelRotatedDirection 1;
BA_ "Remark" SG_ 3221225472 BCS_RRWheelRotatedDirection "";
BA_ "GenSigSendType" SG_ 3221225472 BCS_RRWheelRotatedDirectionVD 1;
BA_ "Remark" SG_ 3221225472 BCS_RRWheelRotatedDirectionVD "";
BA_ "GenSigSendType" SG_ 3221225472 BCS_RLWheelSpd 1;
BA_ "Remark" SG_ 3221225472 BCS_RLWheelSpd "";
BA_ "GenSigSendType" SG_ 3221225472 BCS_RLWheelRotatedDirectionVD 1;
BA_ "Remark" SG_ 3221225472 BCS_RLWheelRotatedDirectionVD "";
BA_ "GenSigSendType" SG_ 3221225472 BCS_RLWheelRotatedDirection 1;
BA_ "Remark" SG_ 3221225472 BCS_RLWheelRotatedDirection "";
BA_ "GenSigSendType" SG_ 3221225472 BCS_RLWheelSpdVD 1;
BA_ "Remark" SG_ 3221225472 BCS_RLWheelSpdVD "";
BA_ "GenSigStartValue" SG_ 3221225472 SCU_6_Checksum 85;
BA_ "GenSigSendType" SG_ 3221225472 SCU_6_Checksum 1;
BA_ "Remark" SG_ 3221225472 SCU_6_Checksum "";
BA_ "GenSigSendType" SG_ 3221225472 SCU_6_MsgCounter 1;
BA_ "Remark" SG_ 3221225472 SCU_6_MsgCounter "";
BA_ "GenSigSendType" SG_ 3221225472 BCS_FRWheelSpd 1;
BA_ "Remark" SG_ 3221225472 BCS_FRWheelSpd "";
BA_ "GenSigSendType" SG_ 3221225472 BCS_FRWheelSpdVD 1;
BA_ "Remark" SG_ 3221225472 BCS_FRWheelSpdVD "";
BA_ "GenSigSendType" SG_ 3221225472 BCS_FRWheelRotatedDirection 1;
BA_ "Remark" SG_ 3221225472 BCS_FRWheelRotatedDirection "";
BA_ "GenSigSendType" SG_ 3221225472 BCS_FRWheelRotatedDirectionVD 1;
BA_ "Remark" SG_ 3221225472 BCS_FRWheelRotatedDirectionVD "";
BA_ "GenSigSendType" SG_ 3221225472 BCS_FLWheelSpd 1;
BA_ "Remark" SG_ 3221225472 BCS_FLWheelSpd "";
BA_ "GenSigSendType" SG_ 3221225472 BCS_FLWheelRotatedDirectionVD 1;
BA_ "Remark" SG_ 3221225472 BCS_FLWheelRotatedDirectionVD "";
BA_ "GenSigSendType" SG_ 3221225472 BCS_FLWheelRotatedDirection 1;
BA_ "Remark" SG_ 3221225472 BCS_FLWheelRotatedDirection "";
BA_ "GenSigSendType" SG_ 3221225472 BCS_FLWheelSpdVD 1;
BA_ "Remark" SG_ 3221225472 BCS_FLWheelSpdVD "";
BA_ "GenSigStartValue" SG_ 3221225472 SCU_5_Checksum 255;
BA_ "GenSigSendType" SG_ 3221225472 SCU_5_Checksum 1;
BA_ "Remark" SG_ 3221225472 SCU_5_Checksum "";
BA_ "GenSigSendType" SG_ 3221225472 BCS_CDDFail 1;
BA_ "Remark" SG_ 3221225472 BCS_CDDFail "";
BA_ "GenSigSendType" SG_ 3221225472 BCS_VehicleStandStillSt 1;
BA_ "Remark" SG_ 3221225472 BCS_VehicleStandStillSt "";
BA_ "GenSigSendType" SG_ 3221225472 BCS_CDDAvailable 1;
BA_ "Remark" SG_ 3221225472 BCS_CDDAvailable "";
BA_ "GenSigSendType" SG_ 3221225472 BCS_CDDActive 1;
BA_ "Remark" SG_ 3221225472 BCS_CDDActive "";
BA_ "GenSigSendType" SG_ 3221225472 BCS_AEBAvailable 1;
BA_ "Remark" SG_ 3221225472 BCS_AEBAvailable "";
BA_ "GenSigSendType" SG_ 3221225472 BCS_AEBActive 1;
BA_ "Remark" SG_ 3221225472 BCS_AEBActive "";
BA_ "GenSigStartValue" SG_ 3221225472 BCS_MasterCylinderPrOffset 150;
BA_ "GenSigSendType" SG_ 3221225472 BCS_MasterCylinderPrOffset 1;
BA_ "Remark" SG_ 3221225472 BCS_MasterCylinderPrOffset "";
BA_ "GenSigSendType" SG_ 3221225472 SCU_5_MsgCounter 1;
BA_ "Remark" SG_ 3221225472 SCU_5_MsgCounter "";
BA_ "GenSigSendType" SG_ 3221225472 BCS_MasterCylinderPr 1;
BA_ "Remark" SG_ 3221225472 BCS_MasterCylinderPr "";
BA_ "GenSigSendType" SG_ 3221225472 BCS_MasterCylinderPrOffsetVD 1;
BA_ "Remark" SG_ 3221225472 BCS_MasterCylinderPrOffsetVD "";
BA_ "GenSigSendType" SG_ 3221225472 BCS_MasterCylinderPrVD 1;
BA_ "Remark" SG_ 3221225472 BCS_MasterCylinderPrVD "";
BA_ "GenSigSendType" SG_ 3221225472 BCS_NoBrakeForce 1;
BA_ "Remark" SG_ 3221225472 BCS_NoBrakeForce "";
BA_ "GenSigStartValue" SG_ 3221225472 SCU_4_Checksum 255;
BA_ "GenSigSendType" SG_ 3221225472 SCU_4_Checksum 1;
BA_ "Remark" SG_ 3221225472 SCU_4_Checksum "";
BA_ "GenSigSendType" SG_ 3221225472 SCU_4_MsgCounter 1;
BA_ "Remark" SG_ 3221225472 SCU_4_MsgCounter "";
BA_ "GenSigSendType" SG_ 3221225472 BCS_HDCErrSt 1;
BA_ "Remark" SG_ 3221225472 BCS_HDCErrSt "";
BA_ "GenSigSendType" SG_ 3221225472 BCS_HDCCtrlSt 1;
BA_ "Remark" SG_ 3221225472 BCS_HDCCtrlSt "";
BA_ "GenSigStartValue" SG_ 3221225472 SCU_3_Checksum 240;
BA_ "GenSigSendType" SG_ 3221225472 SCU_3_Checksum 1;
BA_ "Remark" SG_ 3221225472 SCU_3_Checksum "";
BA_ "GenSigSendType" SG_ 3221225472 SCU_3_MsgCounter 1;
BA_ "Remark" SG_ 3221225472 SCU_3_MsgCounter "";
BA_ "GenSigSendType" SG_ 3221225472 BCS_YawRateSt 1;
BA_ "Remark" SG_ 3221225472 BCS_YawRateSt "";
BA_ "GenSigStartValue" SG_ 3221225472 SCU_2_Checksum 255;
BA_ "GenSigSendType" SG_ 3221225472 SCU_2_Checksum 1;
BA_ "Remark" SG_ 3221225472 SCU_2_Checksum "";
BA_ "GenSigSendType" SG_ 3221225472 SCU_2_MsgCounter 1;
BA_ "Remark" SG_ 3221225472 SCU_2_MsgCounter "";
BA_ "GenSigSendType" SG_ 3221225472 BCS_RRWheelSpdEdgesSumVD 1;
BA_ "Remark" SG_ 3221225472 BCS_RRWheelSpdEdgesSumVD "";
BA_ "GenSigSendType" SG_ 3221225472 BCS_RLWheelSpdEdgesSumVD 1;
BA_ "Remark" SG_ 3221225472 BCS_RLWheelSpdEdgesSumVD "";
BA_ "GenSigSendType" SG_ 3221225472 BCS_FRWheelSpdEdgesSumVD 1;
BA_ "Remark" SG_ 3221225472 BCS_FRWheelSpdEdgesSumVD "";
BA_ "GenSigSendType" SG_ 3221225472 BCS_FLWheelSpdEdgesSumVD 1;
BA_ "Remark" SG_ 3221225472 BCS_FLWheelSpdEdgesSumVD "";
BA_ "GenSigSendType" SG_ 3221225472 BCS_RRWheelSpdEdgesSum 1;
BA_ "Remark" SG_ 3221225472 BCS_RRWheelSpdEdgesSum "";
BA_ "GenSigSendType" SG_ 3221225472 BCS_RLWheelSpdEdgesSum 1;
BA_ "Remark" SG_ 3221225472 BCS_RLWheelSpdEdgesSum "";
BA_ "GenSigSendType" SG_ 3221225472 BCS_FRWheelSpdEdgesSum 1;
BA_ "Remark" SG_ 3221225472 BCS_FRWheelSpdEdgesSum "";
BA_ "GenSigSendType" SG_ 3221225472 BCS_FLWheelSpdEdgesSum 1;
BA_ "Remark" SG_ 3221225472 BCS_FLWheelSpdEdgesSum "";
BA_ "GenSigStartValue" SG_ 3221225472 SCU_1_Checksum 85;
BA_ "GenSigSendType" SG_ 3221225472 SCU_1_Checksum 1;
BA_ "Remark" SG_ 3221225472 SCU_1_Checksum "";
BA_ "GenSigSendType" SG_ 3221225472 BCS_VDCActiveSt 1;
BA_ "Remark" SG_ 3221225472 BCS_VDCActiveSt "";
BA_ "GenSigSendType" SG_ 3221225472 SCU_1_MsgCounter 1;
BA_ "Remark" SG_ 3221225472 SCU_1_MsgCounter "";
BA_ "GenSigStartValue" SG_ 3221225472 BCS_VDCFaultSt 1;
BA_ "GenSigSendType" SG_ 3221225472 BCS_VDCFaultSt 1;
BA_ "Remark" SG_ 3221225472 BCS_VDCFaultSt "";
BA_ "GenSigStartValue" SG_ 3221225472 BCS_ABSFaultSt 1;
BA_ "GenSigSendType" SG_ 3221225472 BCS_ABSFaultSt 1;
BA_ "Remark" SG_ 3221225472 BCS_ABSFaultSt "";
BA_ "GenSigStartValue" SG_ 3221225472 BCS_YawRateOffset 133;
BA_ "GenSigSendType" SG_ 3221225472 BCS_YawRateOffset 1;
BA_ "Remark" SG_ 3221225472 BCS_YawRateOffset "";
BA_ "GenSigSendType" SG_ 640 ADCU_BeamReq 1;
BA_ "Remark" SG_ 640 ADCU_BeamReq "";
BA_ "GenSigSendType" SG_ 640 ADCU_HornRingReq 1;
BA_ "Remark" SG_ 640 ADCU_HornRingReq "";
BA_ "GenSigSendType" SG_ 640 ADCU_TurnLightReq 1;
BA_ "Remark" SG_ 640 ADCU_TurnLightReq "";
BA_ "GenSigSendType" SG_ 640 ADCU_BodyCtrlReq 1;
BA_ "Remark" SG_ 640 ADCU_BodyCtrlReq "";
BA_ "GenSigSendType" SG_ 545 ADCU_SteerAngReq 1;
BA_ "Remark" SG_ 545 ADCU_SteerAngReq "";
BA_ "GenSigSendType" SG_ 545 ADCU_LatCtrlReq 1;
BA_ "Remark" SG_ 545 ADCU_LatCtrlReq "";
BA_ "GenSigSendType" SG_ 544 ADCU_GearLvlReq 1;
BA_ "Remark" SG_ 544 ADCU_GearLvlReq "";
BA_ "GenSigSendType" SG_ 544 ADCU_GearLvlReqVD 1;
BA_ "Remark" SG_ 544 ADCU_GearLvlReqVD "";
BA_ "GenSigSendType" SG_ 544 ADCU_AutoTrqWhlReq 1;
BA_ "Remark" SG_ 544 ADCU_AutoTrqWhlReq "";
BA_ "GenSigSendType" SG_ 544 ADCU_LngCtrlReq 1;
BA_ "Remark" SG_ 544 ADCU_LngCtrlReq "";
BA_ "GenSigSendType" SG_ 544 ADCU_BrakeReq 1;
BA_ "Remark" SG_ 544 ADCU_BrakeReq "";
BA_ "GenSigSendType" SG_ 559 VCU_BrkPedalSt 1;
BA_ "Remark" SG_ 559 VCU_BrkPedalSt "";
BA_ "GenSigSendType" SG_ 557 VCU_GasPedalActPst 1;
BA_ "Remark" SG_ 557 VCU_GasPedalActPst "";
BA_ "GenSigSendType" SG_ 557 VCU_AccElecECFail 1;
BA_ "Remark" SG_ 557 VCU_AccElecECFail "";
BA_ "GenSigSendType" SG_ 557 VCU_VehWheelTorqMax 1;
BA_ "Remark" SG_ 557 VCU_VehWheelTorqMax "";
BA_ "GenSigSendType" SG_ 556 VCU_ActVehWheelTorq 1;
BA_ "Remark" SG_ 556 VCU_ActVehWheelTorq "";
BA_ "GenSigSendType" SG_ 555 VCU_CrntGearLvl 1;
BA_ "Remark" SG_ 555 VCU_CrntGearLvl "";
BA_ "GenSigSendType" SG_ 555 VCU_CrntGearLvlVD 1;
BA_ "Remark" SG_ 555 VCU_CrntGearLvlVD "";
BA_ "GenSigStartValue" SG_ 706 VCU_VehRng 999;
BA_ "GenSigInvalidValue" SG_ 706 VCU_VehRng 1000;
BA_ "GenSigSendType" SG_ 706 VCU_VehRng 1;
BA_ "Remark" SG_ 706 VCU_VehRng "";
BA_ "GenSigTimeoutValue" SG_ 706 VCU_VehRng 1000;
BA_ "GenSigSendType" SG_ 706 VCU_VehDrvMod 1;
BA_ "Remark" SG_ 706 VCU_VehDrvMod "";
BA_ "GenSigSendType" SG_ 706 VCU_VehRdySt 1;
BA_ "Remark" SG_ 706 VCU_VehRdySt "";
BA_ "GenSigSendType" SG_ 554 SCU_StrngWhlIntv 1;
BA_ "Remark" SG_ 554 SCU_StrngWhlIntv "";
BA_ "GenSigSendType" SG_ 554 VCU_GearLeverIntv 1;
BA_ "Remark" SG_ 554 VCU_GearLeverIntv "";
BA_ "GenSigSendType" SG_ 554 SCU_LatCtrlMode 1;
BA_ "Remark" SG_ 554 SCU_LatCtrlMode "";
BA_ "GenSigSendType" SG_ 554 SCU_LngCtrlMode 1;
BA_ "Remark" SG_ 554 SCU_LngCtrlMode "";
BA_ "GenSigInvalidValue" SG_ 705 SRS_DriverSeatBeltSt 3;
BA_ "GenSigSendType" SG_ 705 SRS_DriverSeatBeltSt 1;
BA_ "Remark" SG_ 705 SRS_DriverSeatBeltSt "";
BA_ "GenSigTimeoutValue" SG_ 705 SRS_DriverSeatBeltSt 3;
BA_ "GenSigInvalidValue" SG_ 705 SRS_PsngrSeatBeltSt 3;
BA_ "GenSigSendType" SG_ 705 SRS_PsngrSeatBeltSt 1;
BA_ "Remark" SG_ 705 SRS_PsngrSeatBeltSt "";
BA_ "GenSigTimeoutValue" SG_ 705 SRS_PsngrSeatBeltSt 3;
BA_ "GenSigSendType" SG_ 704 BCM_CtrlAvailable 1;
BA_ "Remark" SG_ 704 BCM_CtrlAvailable "";
BA_ "GenSigSendType" SG_ 704 BCM_HornSt 1;
BA_ "Remark" SG_ 704 BCM_HornSt "";
BA_ "GenSigSendType" SG_ 704 BCM_HazardLampSt 1;
BA_ "Remark" SG_ 704 BCM_HazardLampSt "";
BA_ "GenSigSendType" SG_ 704 BCM_RightTurnLampSt 1;
BA_ "Remark" SG_ 704 BCM_RightTurnLampSt "";
BA_ "GenSigSendType" SG_ 704 BCM_LeftTurnLampSt 1;
BA_ "Remark" SG_ 704 BCM_LeftTurnLampSt "";
BA_ "GenSigSendType" SG_ 704 BCM_HighBeamSt 1;
BA_ "Remark" SG_ 704 BCM_HighBeamSt "";
BA_ "GenSigSendType" SG_ 704 BCM_LowBeamSt 1;
BA_ "Remark" SG_ 704 BCM_LowBeamSt "";
BA_ "GenSigSendType" SG_ 704 BCM_KeySt 1;
BA_ "Remark" SG_ 704 BCM_KeySt "";
BA_ "GenSigInvalidValue" SG_ 553 EPS_StrngWhlTorq 255;
BA_ "GenSigSendType" SG_ 553 EPS_StrngWhlTorq 1;
BA_ "Remark" SG_ 553 EPS_StrngWhlTorq "";
BA_ "GenSigTimeoutValue" SG_ 553 EPS_StrngWhlTorq 255;
BA_ "GenSigInvalidValue" SG_ 553 EPS_SteeringAngleSpd 255;
BA_ "GenSigSendType" SG_ 553 EPS_SteeringAngleSpd 1;
BA_ "Remark" SG_ 553 EPS_SteeringAngleSpd "";
BA_ "GenSigTimeoutValue" SG_ 553 EPS_SteeringAngleSpd 255;
BA_ "GenSigSendType" SG_ 553 EPS_SteeringAngleVD 1;
BA_ "Remark" SG_ 553 EPS_SteeringAngleVD "";
BA_ "GenSigSendType" SG_ 553 EPS_SteeringAngle 1;
BA_ "Remark" SG_ 553 EPS_SteeringAngle "";
BA_ "GenSigSendType" SG_ 553 EPS_SteeringAngleSpdVD 1;
BA_ "Remark" SG_ 553 EPS_SteeringAngleSpdVD "";
BA_ "GenSigSendType" SG_ 552 EPB_SysSt 1;
BA_ "Remark" SG_ 552 EPB_SysSt "";
BA_ "GenSigTimeoutValue" SG_ 552 EPB_SysSt 7;
BA_ "GenSigStartValue" SG_ 551 BCS_ActVehLaltrlAccel 796;
BA_ "GenSigSendType" SG_ 551 BCS_ActVehLaltrlAccel 1;
BA_ "Remark" SG_ 551 BCS_ActVehLaltrlAccel "";
BA_ "GenSigStartValue" SG_ 551 BCS_ActVehLongAccel 796;
BA_ "GenSigSendType" SG_ 551 BCS_ActVehLongAccel 1;
BA_ "Remark" SG_ 551 BCS_ActVehLongAccel "";
BA_ "GenSigStartValue" SG_ 547 BCS_YawRate 2144;
BA_ "GenSigSendType" SG_ 547 BCS_YawRate 1;
BA_ "Remark" SG_ 547 BCS_YawRate "";
BA_ "GenSigSendType" SG_ 384 BCS_VehSpd 1;
BA_ "Remark" SG_ 384 BCS_VehSpd "";
BA_ "GenSigSendType" SG_ 384 BCS_VehSpdVD 1;
BA_ "Remark" SG_ 384 BCS_VehSpdVD "";
BA_ "GenSigSendType" SG_ 384 BCS_ABSActiveSt 1;
BA_ "Remark" SG_ 384 BCS_ABSActiveSt "";
VAL_ 3221225472 VCU_GasPedalVirtualPstVD 1 "Valid" 0 "Not valid" ;
VAL_ 3221225472 VCU_BrkPedalStVD 1 "Valid" 0 "Not valid" ;
VAL_ 3221225472 VCU_GasPedalActPstVD 1 "Valid" 0 "Invalid" ;
VAL_ 3221225472 VCU_LateralAssistBtnInfoVD 1 "Valid" 0 "Invalid" ;
VAL_ 3221225472 VCU_LateralAssistBtnInfo 1 "Pressed " 0 "Not pressed" ;
VAL_ 3221225472 VCU_ACCMaxRecpDecelVD 1 "Valid" 0 "Not valid" ;
VAL_ 3221225472 VCU_ActRecpTorqSt 3 "Reserved" 2 "Faulty" 1 "Normal" 0 "NotIntialized" ;
VAL_ 3221225472 SCU_EStopSwStVD 1 "Valid" 0 "Not valid" ;
VAL_ 3221225472 SCU_EStopSwSt 1 "Pressed" 0 "Not pressed" ;
VAL_ 3221225472 BCM_RightTurnLampFaultSt 1 "Fault" 0 "Not fault" ;
VAL_ 3221225472 BCM_LeftTurnLampFaultSt 1 "Fault" 0 "Not fault" ;
VAL_ 3221225472 BCM_RRDoorAjarSt 1 "Open" 0 "Closed" ;
VAL_ 3221225472 BCM_RLDoorAjarSt 1 "Open" 0 "Closed" ;
VAL_ 3221225472 BCM_PsngrDoorAjarSt 1 "Open" 0 "Closed" ;
VAL_ 3221225472 BCM_DriverDoorAjarSt 1 "Open" 0 "Closed" ;
VAL_ 3221225472 BCM_RearFogLampSt 1 "Active" 0 "Not active" ;
VAL_ 3221225472 BCM_FrontFogLampSt 1 "Active" 0 "Not active" ;
VAL_ 3221225472 BCM_FrontWiperSt 3 "Continuous fast" 2 "Continuous slow" 1 "Error" 0 "OFF" ;
VAL_ 3221225472 EPS_ThermalSt 3 "Temperature Impossible" 2 "Temperature Low" 1 "Temperature High" 0 "Temperature Normal" ;
VAL_ 3221225472 EPS_WarnLamp 1 "Fail present" 0 "Fail not present" ;
VAL_ 3221225472 EPS_StrngWhlTorqVD 1 "Valid" 0 "Not valid" ;
VAL_ 3221225472 EPB_FailSt 1 "Error" 0 "No error" ;
VAL_ 3221225472 EPB_SwitchStVD 1 "Valid" 0 "Not valid                                                       " ;
VAL_ 3221225472 EPB_SwitchSt 3 "Not used                                                                                      " 2 " Applied" 1 " Released                                                       " 0 " Not active                                                        " ;
VAL_ 3221225472 BCS_ActVehLaltrlAccelVD 1 "Valid" 0 "Not valid" ;
VAL_ 3221225472 BCS_ActVehLongAccelVD 1 "Valid" 0 "Not valid" ;
VAL_ 3221225472 BCS_RRWheelSpdVD 1 "Valid" 0 "Not valid" ;
VAL_ 3221225472 BCS_RRWheelRotatedDirection 1 "Backward" 0 "Forward" ;
VAL_ 3221225472 BCS_RRWheelRotatedDirectionVD 1 "Valid" 0 "Not valid" ;
VAL_ 3221225472 BCS_RLWheelRotatedDirectionVD 1 "Valid" 0 "Not valid" ;
VAL_ 3221225472 BCS_RLWheelRotatedDirection 1 "Backward" 0 "Forward" ;
VAL_ 3221225472 BCS_RLWheelSpdVD 1 "Valid" 0 "Not valid" ;
VAL_ 3221225472 BCS_FRWheelSpdVD 1 "Valid" 0 "Not valid" ;
VAL_ 3221225472 BCS_FRWheelRotatedDirection 1 "Backward" 0 "Forward" ;
VAL_ 3221225472 BCS_FRWheelRotatedDirectionVD 1 "Valid" 0 "Not valid" ;
VAL_ 3221225472 BCS_FLWheelRotatedDirectionVD 1 "Valid" 0 "Not valid" ;
VAL_ 3221225472 BCS_FLWheelRotatedDirection 1 "Backward" 0 "Forward" ;
VAL_ 3221225472 BCS_FLWheelSpdVD 1 "Valid" 0 "Not valid" ;
VAL_ 3221225472 BCS_CDDFail 1 "Failure" 0 "Not failure" ;
VAL_ 3221225472 BCS_VehicleStandStillSt 3 "Not used" 2 "Invalid (short unavailability, max 3s)" 1 "standstill" 0 "Not standstill" ;
VAL_ 3221225472 BCS_CDDAvailable 1 "Available" 0 "Not available" ;
VAL_ 3221225472 BCS_CDDActive 1 "Active" 0 "Not active" ;
VAL_ 3221225472 BCS_AEBAvailable 1 "Available" 0 "Not available" ;
VAL_ 3221225472 BCS_AEBActive 1 "Active" 0 "Not active" ;
VAL_ 3221225472 BCS_MasterCylinderPrOffsetVD 1 "Valid" 0 "Invalid" ;
VAL_ 3221225472 BCS_MasterCylinderPrVD 1 "Valid" 0 "Invalid" ;
VAL_ 3221225472 BCS_NoBrakeForce 1 "No brake force" 0 "Exist brake force" ;
VAL_ 3221225472 BCS_HDCErrSt 1 "Error" 0 "No error" ;
VAL_ 3221225472 BCS_HDCCtrlSt 3 "Not used" 2 "On not active braking" 1 "On active braking" 0 "Off" ;
VAL_ 3221225472 BCS_YawRateSt 1 "Valid" 0 "Not valid" ;
VAL_ 3221225472 BCS_RRWheelSpdEdgesSumVD 1 "Valid" 0 "Not valid" ;
VAL_ 3221225472 BCS_RLWheelSpdEdgesSumVD 1 "Valid" 0 "Not valid" ;
VAL_ 3221225472 BCS_FRWheelSpdEdgesSumVD 1 "Valid" 0 "Not valid" ;
VAL_ 3221225472 BCS_FLWheelSpdEdgesSumVD 1 "Valid" 0 "Not valid" ;
VAL_ 3221225472 BCS_VDCActiveSt 1 "Active" 0 "Not active" ;
VAL_ 3221225472 BCS_VDCFaultSt 1 "Fault" 0 "Not Fault" ;
VAL_ 3221225472 BCS_ABSFaultSt 1 "Fault" 0 "Not Fault" ;
VAL_ 640 ADCU_BeamReq 3 "Reserved" 2 "High beam request" 1 "Low beam request" 0 "No request" ;
VAL_ 640 ADCU_HornRingReq 1 "Active" 0 "Not active" ;
VAL_ 640 ADCU_TurnLightReq 3 "Emergency light" 2 "Turn right light" 1 "Turn left light" 0 "No request" ;
VAL_ 640 ADCU_BodyCtrlReq 1 "Enable" 0 "Disable" ;
VAL_ 545 ADCU_LatCtrlReq 1 "Auto" 0 "Manual" ;
VAL_ 544 ADCU_GearLvlReq 7 "Reserved" 6 "Reserved" 5 "Reserved" 4 "Drive" 3 "Neutral" 2 "Reversed" 1 "Park" 0 "No request" ;
VAL_ 544 ADCU_GearLvlReqVD 1 "Request" 0 "No request" ;
VAL_ 544 ADCU_LngCtrlReq 1 "Auto" 0 "Manual" ;
VAL_ 559 VCU_BrkPedalSt 1 "Pressed" 0 "Not pressed" ;
VAL_ 557 VCU_AccElecECFail 1 "Failure" 0 "No failure" ;
VAL_ 555 VCU_CrntGearLvl 7 "Not used" 6 "Not used" 5 "Not used" 4 "'P' Park gear" 3 "'R' Reverse gear" 2 "'N' Neutral gear" 1 "'D' Drive gear" 0 "Invalid" ;
VAL_ 555 VCU_CrntGearLvlVD 1 "Valid" 0 "Not valid" ;
VAL_ 706 VCU_VehDrvMod 7 "Reserved" 6 "I-pedal Mode" 5 "SPORT Mode" 4 "Driving Mode" 3 "Normal Mode" 2 "ECO Mode" 1 "ECO+ Mode" 0 "Invalid" ;
VAL_ 706 VCU_VehRdySt 1 "Ready" 0 "Not ready" ;
VAL_ 554 SCU_StrngWhlIntv 1 "Driver override" 0 "No override" ;
VAL_ 554 VCU_GearLeverIntv 1 "With intervention" 0 "Without intervention" ;
VAL_ 554 SCU_LatCtrlMode 3 "Fault" 2 "Auto" 1 "Quit" 0 "Manual" ;
VAL_ 554 SCU_LngCtrlMode 3 "Fault" 2 "Auto" 1 "Quit" 0 "Manual" ;
VAL_ 705 SRS_DriverSeatBeltSt 3 "Invalid" 2 "Not used" 1 "Unfastened" 0 "Fastened " ;
VAL_ 705 SRS_PsngrSeatBeltSt 3 "Invalid" 2 "Not used" 1 "Unfastened" 0 "Fastened " ;
VAL_ 704 BCM_CtrlAvailable 1 "Available" 0 "Not available" ;
VAL_ 704 BCM_HornSt 1 "Active" 0 "Not active" ;
VAL_ 704 BCM_HazardLampSt 1 "Active" 0 "Not active" ;
VAL_ 704 BCM_RightTurnLampSt 1 "Active" 0 "Not active" ;
VAL_ 704 BCM_LeftTurnLampSt 1 "Active" 0 "Not active" ;
VAL_ 704 BCM_HighBeamSt 1 "Active" 0 "Not active" ;
VAL_ 704 BCM_LowBeamSt 1 "Active" 0 "Not active" ;
VAL_ 704 BCM_KeySt 3 "Crank                                " 2 "On" 1 "Acc" 0 "Off" ;
VAL_ 553 EPS_SteeringAngleVD 1 "Valid" 0 "Not valid" ;
VAL_ 553 EPS_SteeringAngleSpdVD 1 "Valid" 0 "Not valid" ;
VAL_ 552 EPB_SysSt 7 "Fault(not sure position)" 6 "Not used" 5 "Not used" 4 "Disengaged" 3 "Applying" 2 "Releasing" 1 "Apply (fully applied)" 0 "Release (fully released)" ;
VAL_ 384 BCS_VehSpdVD 1 "Valid" 0 "Not Valid" ;
VAL_ 384 BCS_ABSActiveSt 1 "Active" 0 "Not active" ;
